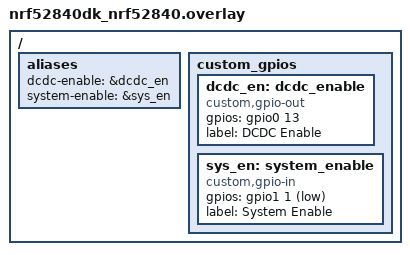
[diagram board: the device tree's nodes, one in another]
/ {
    aliases {
        dcdc-enable = &dcdc_en;
        system-enable = &sys_en;
    };

    custom_gpios {
        dcdc_en: dcdc_enable {
            compatible = "custom,gpio-out";
            gpios = <&gpio0 13 GPIO_ACTIVE_HIGH>;
            label = "DCDC Enable";
        };

        sys_en: system_enable {
            compatible = "custom,gpio-in";
            gpios = <&gpio1 1 GPIO_ACTIVE_LOW>;
            label = "System Enable";
        };
    };
};
